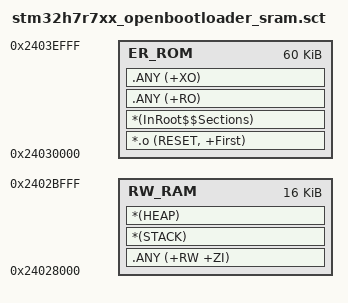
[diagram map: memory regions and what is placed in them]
; *************************************************************
; *** Scatter-Loading Description File generated by uVision ***
; *************************************************************

LOAD_FLASH 0x24030000 0x0000F000  {    ; load region size_region
  ER_ROM 0x24030000 0x0000F000  {  ; load address = execution address
   *.o (RESET, +First)
   *(InRoot$$Sections)
   .ANY (+RO)
   .ANY (+XO)
  }
  RW_RAM 0x24028000  0x4000  {
   .ANY (+RW +ZI)
   *(STACK)
   *(HEAP)
  }
}
